# SF32LB58x register map
File version: 1.0
CPU: CM33 r0p1, little endian, MPU, FPU, 3 interrupt priority bits
Registers are 32-bit, read-write, reset 0x0 unless marked. A register's access mark holds for its fields unless they carry their own. Offsets are from the block's base; [hi:lo] are bit positions; {n}, {i} and the like mark numbered series; 'fields as' and 'values as' point back to an identical list.

## AUDPRC
Base 0x40025000
0x00 ID reset 0xA0000
  [31:0] REV — revision id
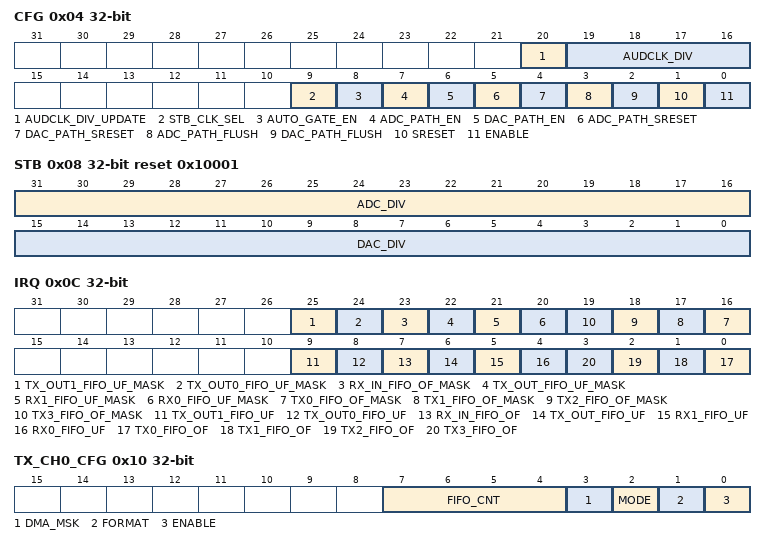
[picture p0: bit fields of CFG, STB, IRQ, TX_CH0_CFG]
0x04 CFG
  [20] AUDCLK_DIV_UPDATE — audprc clock divider update, write 1 to update
  [19:16] AUDCLK_DIV — audprc clock divider, 0 and 1 means divide by 1
  [9] STB_CLK_SEL — audio strobe clock select 0: use xtal clock to generate strobe 1: use pll clock to generate strobe
  [8] AUTO_GATE_EN — auto clock gating enable, high active
  [7] ADC_PATH_EN — adc path enable
  [6] DAC_PATH_EN — dac path enable
  [5] ADC_PATH_SRESET — adc path software reset, high active
  [4] DAC_PATH_SRESET — dac path software reset, high active
  [3] ADC_PATH_FLUSH — adc path fifo flush, high active
  [2] DAC_PATH_FLUSH — dac path fifo flush, high active
  [1] SRESET — audprc software reset, high active
  [0] ENABLE — audprc enable
0x08 STB reset 0x10001
  [31:16] ADC_DIV — adc strobe divider
  [15:0] DAC_DIV — dac strobe divider
0x0C IRQ
  [25] TX_OUT1_FIFO_UF_MASK — tx_out channel 1 fifo underflow mask, 0: mask the interrupt
  [24] TX_OUT0_FIFO_UF_MASK — tx_out channel 0 fifo underflow mask, 0: mask the interrupt
  [23] RX_IN_FIFO_OF_MASK — rx input fifo overflow mask, 0: mask the interrupt
  [22] TX_OUT_FIFO_UF_MASK — tx output fifo underflow mask, 0: mask the interrupt
  [21] RX1_FIFO_UF_MASK — rx channel 1 fifo underflow mask, 0: mask the interrupt
  [20] RX0_FIFO_UF_MASK — rx channel 0 fifo underflow mask, 0: mask the interrupt
  [n+16] TX{n}_FIFO_OF_MASK (n=0..3) — tx channel {n} fifo overflow mask, 0: mask the interrupt
  [9] TX_OUT1_FIFO_UF — tx_out channel 1 fifo underflow, write 1 to clear
  [8] TX_OUT0_FIFO_UF — tx_out channel 0 fifo underflow, write 1 to clear
  [7] RX_IN_FIFO_OF — rx input fifo overflow, write 1 to clear
  [6] TX_OUT_FIFO_UF — tx output fifo underflow, write 1 to clear
  [5] RX1_FIFO_UF — rx channel 1 fifo underflow, write 1 to clear
  [4] RX0_FIFO_UF — rx channel 0 fifo underflow, write 1 to clear
  [n] TX{n}_FIFO_OF (n=0..3) — tx channel {n} fifo overflow, write 1 to clear
0x10 TX_CH0_CFG
  [7:4] FIFO_CNT — tx fifo counter
  [3] DMA_MSK — 1: mask the dma request for tx ch0
  [2] MODE — tx mode 1'h0: mono mode 1'h1: stereo mode This bit is only used for 16-bit mode, in 24-bit mode, channel can only be set in mono mode. In 16-bit stereo mode, tx channel 1 is not working, both left and right audio data comes from channel 0.
  [1] FORMAT — tx format 0: 16-bit mode 1: 24-bit mode
  [0] ENABLE — tx channel 0 enable
{0x14+8i} TX_CH{i}_ENTRY (i=0..3)
  [31:0] DATA — tx channel {i} data entry
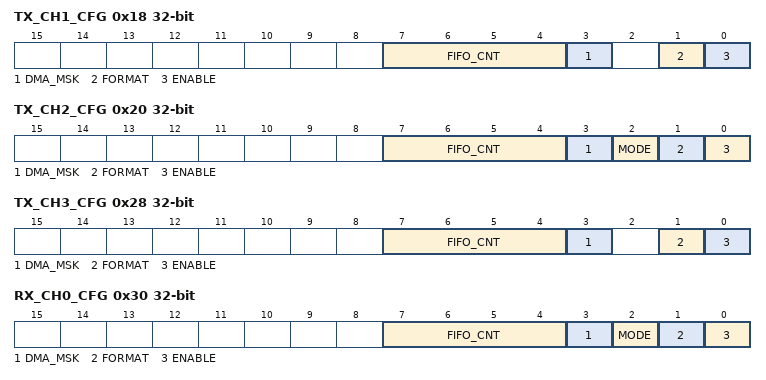
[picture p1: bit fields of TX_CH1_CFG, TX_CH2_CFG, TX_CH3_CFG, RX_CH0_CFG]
0x18 TX_CH1_CFG
  [7:4] FIFO_CNT — tx fifo counter
  [3] DMA_MSK — 1: mask the dma request for tx ch1
  [1] FORMAT — tx format 0: 16-bit mode 1: 24-bit mode
  [0] ENABLE — tx channel 0 enable
0x20 TX_CH2_CFG
  [7:4] FIFO_CNT — tx fifo counter
  [3] DMA_MSK — 1: mask the dma request for tx ch2
  [2] MODE — tx mode 1'h0: mono mode 1'h1: stereo mode This bit is only used for 16-bit mode, in 24-bit mode, channel can only be set in mono mode. In 16-bit stereo mode, tx channel 3 is not working, both left and right audio data comes from channel 2.
  [1] FORMAT — tx format 0: 16-bit mode 1: 24-bit mode
  [0] ENABLE — tx channel 0 enable
0x28 TX_CH3_CFG
  [7:4] FIFO_CNT — tx fifo counter
  [3] DMA_MSK — 1: mask the dma request for tx ch3
  [1] FORMAT — tx format 0: 16-bit mode 1: 24-bit mode
  [0] ENABLE — tx channel 0 enable
0x30 RX_CH0_CFG
  [7:4] FIFO_CNT — rx fifo counter
  [3] DMA_MSK — 1: mask the dma request for rx ch0
  [2] MODE — rx mode 1'h0: mono mode 1'h1: stereo mode This bit is only used for 16-bit mode, in 24-bit mode, channel can only be set in mono mode. In 16-bit stereo mode, rx channel 1 is not working, both left and right audio data comes from channel 0.
  [1] FORMAT — rx format 0: 16-bit mode 1: 24-bit mode
  [0] ENABLE — rx channel 0 enable
0x34 RX_CH0_ENTRY
  [31:0] DATA — rx channel 0 data entry
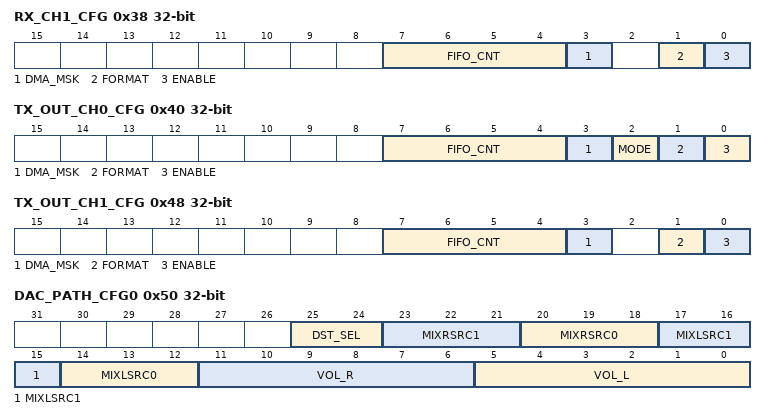
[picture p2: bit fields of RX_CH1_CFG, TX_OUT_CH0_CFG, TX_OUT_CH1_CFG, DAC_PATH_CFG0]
0x38 RX_CH1_CFG
  [7:4] FIFO_CNT — rx fifo counter
  [3] DMA_MSK — 1: mask the dma request for rx ch1
  [1] FORMAT — rx format 0: 16-bit mode 1: 24-bit mode
  [0] ENABLE — rx channel 1 enable
0x3C RX_CH1_ENTRY
  [31:0] DATA — rx channel 1 data entry
0x40 TX_OUT_CH0_CFG
  [7:4] FIFO_CNT — tx out fifo counter
  [3] DMA_MSK — 1: mask the dma request for tx out ch0
  [2] MODE — tx out mode 1'h0: mono mode 1'h1: stereo mode This bit is only used for 16-bit mode, in 24-bit mode, channel can only be set in mono mode. In 16-bit stereo mode, rx channel 1 is not working, both left and right audio data comes from channel 0.
  [1] FORMAT — tx out format 0: 16-bit mode 1: 24-bit mode
  [0] ENABLE — tx out channel 0 enable
0x44 TX_OUT_CH0_ENTRY
  [31:0] DATA — tx out channel 0 data entry
0x48 TX_OUT_CH1_CFG
  [7:4] FIFO_CNT — tx out fifo counter
  [3] DMA_MSK — 1: mask the dma request for tx out ch1
  [1] FORMAT — tx out format 0: 16-bit mode 1: 24-bit mode
  [0] ENABLE — tx out channel 1 enable
0x4C TX_OUT_CH1_ENTRY
  [31:0] DATA — tx out channel 1 data entry
0x50 DAC_PATH_CFG0
  [25:24] DST_SEL — dac path destination select 2'h0: select audio codec 2'h1: select external interface 2'h2: select apb interface 2'h3: reserved
  [23:21] MIXRSRC1 — dac mixer right channel input source0 select 3'h0:tx ch0 3'h1:tx ch1 3'h2:tx ch2 3'h3:tx ch3 3'h4:mute other: mute
  [20:18] MIXRSRC0 — dac mixer right channel input source0 select 3'h0:tx ch0 3'h1:tx ch1 3'h2:tx ch2 3'h3:tx ch3 3'h4:mute other: mute
  [17:15] MIXLSRC1 — dac mixer left channel input source1 select 3'h0:tx ch0 3'h1:tx ch1 3'h2:tx ch2 3'h3:tx ch3 3'h4:mute other: mute
  [14:12] MIXLSRC0 — dac mixer left channel input source0 select 3'h0:tx ch0 3'h1:tx ch1 3'h2:tx ch2 3'h3:tx ch3 3'h4:mute other: mute
  [11:6] VOL_R — volume control from -18~13dB, step is 0.5dB 6'h0: -18dB 6'h1: -17.5dB ...... 6'h3e: 13dB 6'h3f: mute
  [5:0] VOL_L — volume control from -18~13dB, step is 0.5dB 6'h0: -18dB 6'h1: -17.5dB ...... 6'h3e: 13dB 6'h3f: mute
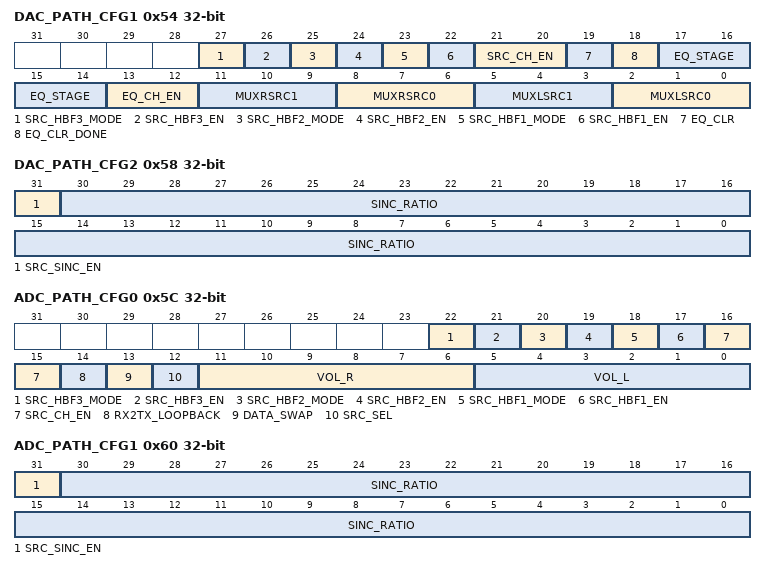
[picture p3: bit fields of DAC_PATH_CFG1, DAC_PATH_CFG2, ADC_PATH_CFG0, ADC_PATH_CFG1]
0x54 DAC_PATH_CFG1
  [27] SRC_HBF3_MODE — 3rd stage hbf mode: 0: upsampling 1: downsampling
  [26] SRC_HBF3_EN — 3rd stage hbf enable
  [25] SRC_HBF2_MODE — 2nd stage hbf mode: 0: upsampling 1: downsampling
  [24] SRC_HBF2_EN — 2nd stage hbf enable
  [23] SRC_HBF1_MODE — 1st stage hbf mode: 0: upsampling 1: downsampling
  [22] SRC_HBF1_EN — 1st stage hbf enable
  [21:20] SRC_CH_EN — source rate converter channel enable
  [19] EQ_CLR — equalizer clear request
  [18] EQ_CLR_DONE — equalizer clear done flag
  [17:14] EQ_STAGE — set equalizer stage, max is 10.
  [13:12] EQ_CH_EN — equalizer channel enable 2'b11: enable both channel 2'b10: enable right chanel only 2'b01: enable left channel only 2'b00: bypass equalizer
  [11:9] MUXRSRC1 — dac mux right channel input source0 select 3'h0:tx ch0 3'h1:tx ch1 3'h2:rx ch0 3'h3:rx ch1 3'h4:mute other: mute
  [8:6] MUXRSRC0 — dac mux right channel input source0 select 3'h0:tx ch0 3'h1:tx ch1 3'h2:rx ch0 3'h3:rx ch1 3'h4:mute other: mute
  [5:3] MUXLSRC1 — dac mux left channel input source1 select 3'h0:tx ch0 3'h1:tx ch1 3'h2:rx ch0 3'h3:rx ch1 3'h4:mute other: mute
  [2:0] MUXLSRC0 — dac mux left channel input source0 select 3'h0:tx ch0 3'h1:tx ch1 3'h2:rx ch0 3'h3:rx ch1 3'h4:mute other: mute
0x58 DAC_PATH_CFG2
  [31] SRC_SINC_EN — sinc filter enable
  [30:0] SINC_RATIO — sinc filter ratio, s31.30 format. Range from 0~2
0x5C ADC_PATH_CFG0
  [22] SRC_HBF3_MODE — 3rd stage hbf mode: 0: upsampling 1: downsampling
  [21] SRC_HBF3_EN — 3rd stage hbf enable
  [20] SRC_HBF2_MODE — 2nd stage hbf mode: 0: upsampling 1: downsampling
  [19] SRC_HBF2_EN — 2nd stage hbf enable
  [18] SRC_HBF1_MODE — 1st stage hbf mode: 0: upsampling 1: downsampling
  [17] SRC_HBF1_EN — 1st stage hbf enable
  [16:15] SRC_CH_EN — source rate converter channel enable
  [14] RX2TX_LOOPBACK — rx to tx loopback enable
  [13] DATA_SWAP — swap adc path left and right channel data
  [12] SRC_SEL — adc path source select 1'h0: select audio codec 1'h1: select external interface
  [11:6] VOL_R — volume control from -18~13dB, step is 0.5dB 6'h0: -18dB 6'h1: -17.5dB ...... 6'h3e: 13dB 6'h3f: mute
  [5:0] VOL_L — volume control from -18~13dB, step is 0.5dB 6'h0: -18dB 6'h1: -17.5dB ...... 6'h3e: 13dB 6'h3f: mute
0x60 ADC_PATH_CFG1
  fields as DAC_PATH_CFG2
{0x70+4i} DAC_EQ_CFG{i} (i=0..49)
  [23:0] COEF
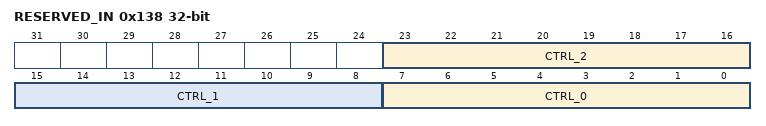
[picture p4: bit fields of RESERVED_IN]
0x138 RESERVED_IN
  [23:16] CTRL_2 — reserved control 2
  [15:8] CTRL_1 — reserved control 1
  [7:0] CTRL_0 — reserved control 0
0x13C RESERVED_OUT
  [7:0] STAT — reserved status
